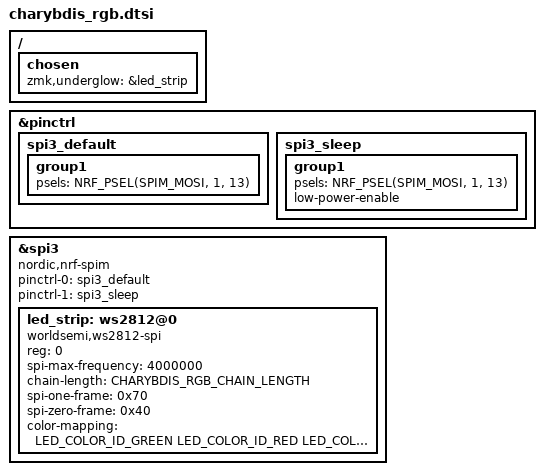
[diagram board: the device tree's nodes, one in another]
#include <dt-bindings/led/led.h>

#ifndef CHARYBDIS_RGB_CHAIN_LENGTH
#error "CHARYBDIS_RGB_CHAIN_LENGTH must be defined before including charybdis_rgb.dtsi"
#endif

&pinctrl {
    spi3_default: spi3_default {
        group1 {
            psels = <NRF_PSEL(SPIM_MOSI, 1, 13)>;
        };
    };

    spi3_sleep: spi3_sleep {
        group1 {
            psels = <NRF_PSEL(SPIM_MOSI, 1, 13)>;
            low-power-enable;
        };
    };
};

&spi3 {
    compatible = "nordic,nrf-spim";
    status = "okay";
    pinctrl-0 = <&spi3_default>;
    pinctrl-1 = <&spi3_sleep>;
    pinctrl-names = "default", "sleep";

    led_strip: ws2812@0 {
        compatible = "worldsemi,ws2812-spi";
        reg = <0>;
        spi-max-frequency = <4000000>;
        chain-length = <CHARYBDIS_RGB_CHAIN_LENGTH>;
        spi-one-frame = <0x70>;
        spi-zero-frame = <0x40>;
        color-mapping = <LED_COLOR_ID_GREEN LED_COLOR_ID_RED LED_COLOR_ID_BLUE>;
    };
};

/ {
    chosen {
        zmk,underglow = &led_strip;
    };
};
